# ISS_TOP register map
Vendor: Texas Instruments
Peripheral module from a debugger description file (folder omap4460).
Registers are 32-bit, access not given, reset 0x0 unless marked. A register's access mark holds for its fields unless they carry their own. Offsets are as the file gives them; lines under a group give offsets from that group; [hi:lo] are bit positions; {n}, {i} and the like mark numbered series; 'fields as' and 'values as' point back to an identical list; <NAME> marks a mode.

## ISS_TOP
0x00 ISS_HL_REVISION ro reset not defined — IP Revision Identifier (X.Y.R) Used by software to track features, bugs, and compatibility
  [31:0] REVISION — IP Revision
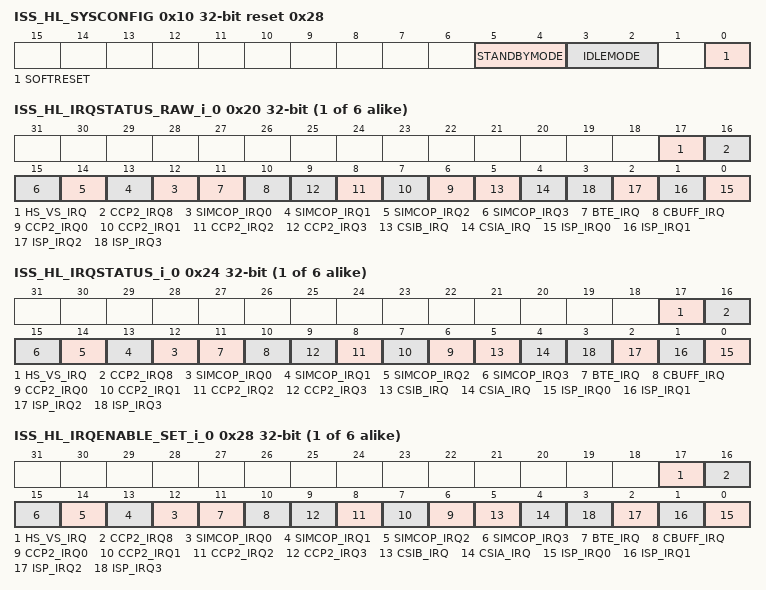
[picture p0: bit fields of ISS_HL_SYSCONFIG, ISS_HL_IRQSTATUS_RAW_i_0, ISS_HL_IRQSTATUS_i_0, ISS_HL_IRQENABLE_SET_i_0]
0x10 ISS_HL_SYSCONFIG access per field reset 0x28 — Clock management configuration
  [5:4] STANDBYMODE rw — Master interface power management, standby/Wait control
    0=Force-standby. MStandby is asserted unconditionally.; 1=No-standby. MStandby is never asserted.; 3=Smart-standby; 2=Smart-standby
  [3:2] IDLEMODE rw — IDLE protocol configuration
    0=Force-idle; 1=No-idle; 3=Smart-idle; 2=Smart-idle
  [0] SOFTRESET rw — Software reset.
    0=SOFTRESET_0_w (No action); 1=SOFTRESET_1_w (Initiate software reset); 1=SOFTRESET_1_r (Reset (software or other) ongoing); 0=SOFTRESET_0_r (Reset done, no pending action)
{0x20+0x10*i} ISS_HL_IRQSTATUS_RAW_i_{i} access per field (i=0..5) — Per-event raw interrupt status vector, line 0. Raw status is set even if event is not enabled by setting the register.
  [17] HS_VS_IRQ rw — HS or VS synchronization event. This event is triggered if a rising or falling edge is detected on the HS or VS signal (after the video port mux). The rising or falling edge and the HS or VS signal selection is chosen with the ISS_CTRL.SYNC_DETECT bit field.
    0=HS_VS_IRQ_0_w (No action); 1=HS_VS_IRQ_1_w (Set event (debug)); 1=HS_VS_IRQ_1_r (Event pending); 0=HS_VS_IRQ_0_r (No event pending)
  [16] CCP2_IRQ8 ro — Event generated by the CCP2 receiver
    1=CCP2_IRQ8_1_r (Event pending); 0=CCP2_IRQ8_0_r (No event pending)
  [n+12] SIMCOP_IRQ{n} ro (n=0..3) — Event generated by SIMCOP
    1=SIMCOP_IRQ{n}_1_r (Event pending); 0=SIMCOP_IRQ{n}_0_r (No event pending)
  [11] BTE_IRQ ro — Event generated by the burst translation engine
    1=BTE_IRQ_1_r (Event pending); 0=BTE_IRQ_0_r (No event pending)
  [10] CBUFF_IRQ ro — Event generated by the circular buffer
    1=CBUFF_IRQ_1_r (Event pending); 0=CBUFF_IRQ_0_r (No event pending)
  [n+6] CCP2_IRQ{n} ro (n=0..3) — Event generated by the CCP2 receiver
    1=CCP2_IRQ{n}_1_r (Event pending); 0=CCP2_IRQ{n}_0_r (No event pending)
  [5] CSIB_IRQ ro — Event generated by the CSI2 receiver #b
    1=CSIB_IRQ_1_r (Event pending); 0=CSIB_IRQ_0_r (No event pending)
  [4] CSIA_IRQ ro — Event generated by the CSI2 receiver #a
    1=CSIA_IRQ_1_r (Event pending); 0=CSIA_IRQ_0_r (No event pending)
  [n] ISP_IRQ{n} ro (n=0..3) — Combined interrupt event provided by the ISP.
    1=ISP_IRQ{n}_1_r (Event pending); 0=ISP_IRQ{n}_0_r (No event pending)
{0x24+0x10*i} ISS_HL_IRQSTATUS_i_{i} (i=0..5) — Per-event 'enabled' interrupt status vector, line 0. Enabled status is not set unless event is enabled by setting the register.
  [17] HS_VS_IRQ — HS or VS synchronization event. This event is triggered if a rising or falling edge is detected on the HS or VS signal (after the video port mux). The rising or falling edge and the HS or VS signal selection is chosen with the ISS_CTRL.SYNC_DETECT bit field. (access RW W1toSet)
    0=HS_VS_IRQ_0_w (No action); 1=HS_VS_IRQ_1_w (Clear (raw) event); 1=HS_VS_IRQ_1_r (Event pending); 0=HS_VS_IRQ_0_r (No (enabled) event pending)
  [16] CCP2_IRQ8 ro — Event generated by the CCP2 receiver
    1=CCP2_IRQ8_1_r (Event pending); 0=CCP2_IRQ8_0_r (No (enabled) event pending)
  [n+12] SIMCOP_IRQ{n} ro (n=0..3) — Event generated by SIMCOP
    1=SIMCOP_IRQ{n}_1_r (Event pending); 0=SIMCOP_IRQ{n}_0_r (No (enabled) event pending)
  [11] BTE_IRQ ro — Event generated by the burst translation engine
    1=BTE_IRQ_1_r (Event pending); 0=BTE_IRQ_0_r (No (enabled) event pending)
  [10] CBUFF_IRQ ro — Event generated by the circular buffer
    1=CBUFF_IRQ_1_r (Event pending); 0=CBUFF_IRQ_0_r (No (enabled) event pending)
  [n+6] CCP2_IRQ{n} ro (n=0..3) — Event generated by the CCP2 receiver
    1=CCP2_IRQ{n}_1_r (Event pending); 0=CCP2_IRQ{n}_0_r (No (enabled) event pending)
  [5] CSIB_IRQ ro — Event generated by the CSI2 receiver #b
    1=CSIB_IRQ_1_r (Event pending); 0=CSIB_IRQ_0_r (No (enabled) event pending)
  [4] CSIA_IRQ ro — Event generated by the CSI2 receiver #a
    1=CSIA_IRQ_1_r (Event pending); 0=CSIA_IRQ_0_r (No (enabled) event pending)
  [n] ISP_IRQ{n} ro (n=0..3) — Combined interrupt event provided by the ISP.
    1=ISP_IRQ{n}_1_r (Event pending); 0=ISP_IRQ{n}_0_r (No (enabled) event pending)
{0x28+0x10*i} ISS_HL_IRQENABLE_SET_i_{i} (i=0..5) — Per-event interrupt enable bit vector Write 1 to set (enable interrupt). Readout equal to corresponding _CLR register.
  [17] HS_VS_IRQ — HS or VS synchronization event. This event is triggered if a rising or falling edge is detected on the HS or VS signal (after the video port mux). The rising or falling edge and the HS or VS signal selection is chosen with the ISS_CTRL.SYNC_DETECT bit field. (access RW W1toSet)
    0=HS_VS_IRQ_0_w (No action); 1=HS_VS_IRQ_1_w (Enable interrupt); 1=HS_VS_IRQ_1_r (Interrupt enabled); 0=HS_VS_IRQ_0_r (Interrupt disabled (masked))
  [16] CCP2_IRQ8 — Event generated by the CCP2 receiver (access RW W1toSet)
    0=CCP2_IRQ8_0_w (No action Write 0x1: Enable interrupt); 1=CCP2_IRQ8_1_r (Interrupt enabled Read 0x0: Interrupt disabled (masked))
  [n+12] SIMCOP_IRQ{n} (n=0..3) — Event generated by SIMCOP (access RW W1toSet)
    0=SIMCOP_IRQ{n}_0_w (No action); 1=SIMCOP_IRQ{n}_1_w (Enable interrupt); 1=SIMCOP_IRQ{n}_1_r (Interrupt enabled); 0=SIMCOP_IRQ{n}_0_r (Interrupt disabled (masked))
  [11] BTE_IRQ — Event generated by the burst translation engine (access RW W1toSet)
    0=BTE_IRQ_0_w (No action); 1=BTE_IRQ_1_w (Enable interrupt); 1=BTE_IRQ_1_r (Interrupt enabled); 0=BTE_IRQ_0_r (Interrupt disabled (masked))
  [10] CBUFF_IRQ — Event generated by the circular buffer (access RW W1toSet)
    0=CBUFF_IRQ_0_w (No action); 1=CBUFF_IRQ_1_w (Enable interrupt); 1=CBUFF_IRQ_1_r (Interrupt enabled); 0=CBUFF_IRQ_0_r (Interrupt disabled (masked))
  [n+6] CCP2_IRQ{n} (n=0..3) — Event generated by the CCP2 receiver (access RW W1toSet)
    0=CCP2_IRQ{n}_0_w (No action); 1=CCP2_IRQ{n}_1_w (Enable interrupt); 1=CCP2_IRQ{n}_1_r (Interrupt enabled); 0=CCP2_IRQ{n}_0_r (Interrupt disabled (masked))
  [5] CSIB_IRQ — Event generated by the CSI2 receiver #b (access RW W1toSet)
    0=CSIB_IRQ_0_w (No action); 1=CSIB_IRQ_1_w (Enable interrupt); 1=CSIB_IRQ_1_r (Interrupt enabled); 0=CSIB_IRQ_0_r (Interrupt disabled (masked))
  [4] CSIA_IRQ — Event generated by the CSI2 receiver #a (access RW W1toSet)
    0=CSIA_IRQ_0_w (No action); 1=CSIA_IRQ_1_w (Enable interrupt); 1=CSIA_IRQ_1_r (Interrupt enabled); 0=CSIA_IRQ_0_r (Interrupt disabled (masked))
  [n] ISP_IRQ{n} (n=0..3) — Combined interrupt event provided by the ISP. (access RW W1toSet)
    0=ISP_IRQ{n}_0_w (No action); 1=ISP_IRQ{n}_1_w (Enable interrupt); 1=ISP_IRQ{n}_1_r (Interrupt enabled); 0=ISP_IRQ{n}_0_r (Interrupt disabled (masked))
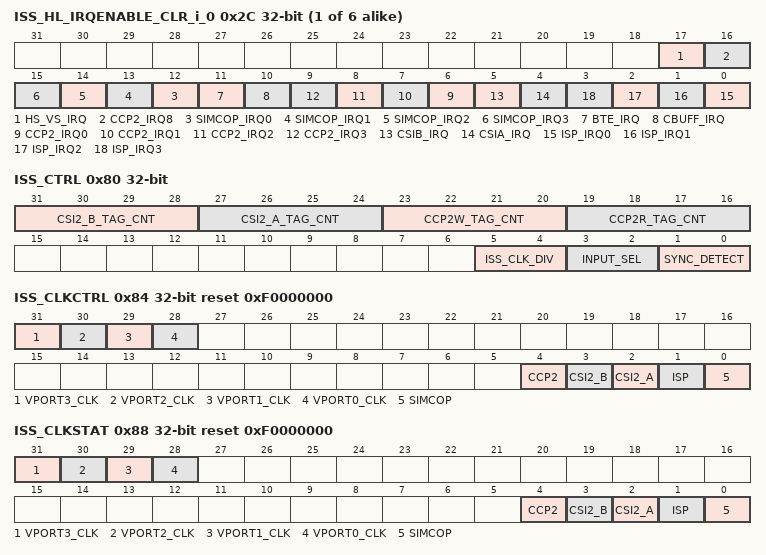
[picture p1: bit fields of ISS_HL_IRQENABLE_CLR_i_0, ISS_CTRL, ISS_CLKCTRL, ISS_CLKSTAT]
{0x2C+0x10*i} ISS_HL_IRQENABLE_CLR_i_{i} (i=0..5) — Per-event interrupt enable bit vector Write 1 to clear (disable interrupt). Readout equal to corresponding _SET register.
  [17] HS_VS_IRQ — HS or VS synchronization event. This event is triggered if a rising or falling edge is detected on the HS or VS signal (after the video port mux). The rising or falling edge and the HS or VS signal selection is chosen with the ISS_CTRL.SYNC_DETECT bit field. (access RW W1toClr)
    0=HS_VS_IRQ_0_w (No action); 1=HS_VS_IRQ_1_w (Disable interrupt); 1=HS_VS_IRQ_1_r (Interrupt enabled); 0=HS_VS_IRQ_0_r (Interrupt disabled (masked))
  [16] CCP2_IRQ8 — Event generated by the CCP2 receiver (access RW W1toSet)
    values as ISS_HL_IRQENABLE_SET_i_0.CCP2_IRQ8
  [n+12] SIMCOP_IRQ{n} (n=0..3) — Event generated by SIMCOP (access RW W1toClr)
    0=SIMCOP_IRQ{n}_0_w (No action); 1=SIMCOP_IRQ{n}_1_w (Disable interrupt); 1=SIMCOP_IRQ{n}_1_r (Interrupt enabled); 0=SIMCOP_IRQ{n}_0_r (Interrupt disabled (masked))
  [11] BTE_IRQ — Event generated by the BTE (access RW W1toClr)
    0=BTE_IRQ_0_w (No action); 1=BTE_IRQ_1_w (Disable interrupt); 1=BTE_IRQ_1_r (Interrupt enabled); 0=BTE_IRQ_0_r (Interrupt disabled (masked))
  [10] CBUFF_IRQ — Event generated by the CBUFF (access RW W1toClr)
    0=CBUFF_IRQ_0_w (No action); 1=CBUFF_IRQ_1_w (Disable interrupt); 1=CBUFF_IRQ_1_r (Interrupt enabled); 0=CBUFF_IRQ_0_r (Interrupt disabled (masked))
  [n+6] CCP2_IRQ{n} (n=0..3) — Event generated by the CCP2 receiver (access RW W1toClr)
    0=CCP2_IRQ{n}_0_w (No action); 1=CCP2_IRQ{n}_1_w (Disable interrupt); 1=CCP2_IRQ{n}_1_r (Interrupt enabled); 0=CCP2_IRQ{n}_0_r (Interrupt disabled (masked))
  [5] CSIB_IRQ — Event generated by the CSI2 receiver b (access RW W1toClr)
    0=CSIB_IRQ_0_w (No action); 1=CSIB_IRQ_1_w (Disable interrupt); 1=CSIB_IRQ_1_r (Interrupt enabled); 0=CSIB_IRQ_0_r (Interrupt disabled (masked))
  [4] CSIA_IRQ — Event generated by the CSI2 receiver a (access RW W1toClr)
    0=CSIA_IRQ_0_w (No action); 1=CSIA_IRQ_1_w (Disable interrupt); 1=CSIA_IRQ_1_r (Interrupt enabled); 0=CSIA_IRQ_0_r (Interrupt disabled (masked))
  [n] ISP_IRQ{n} (n=0..3) — Combined interrupt event provided by the ISP. (access RW W1toClr)
    0=ISP_IRQ{n}_0_w (No action); 1=ISP_IRQ{n}_1_w (Disable interrupt); 1=ISP_IRQ{n}_1_r (Interrupt enabled); 0=ISP_IRQ{n}_0_r (Interrupt disabled (masked))
0x80 ISS_CTRL access per field — ISS control register
  [31:28] CSI2_B_TAG_CNT rw — Defines the maximum number of tags that could be used by the CSI2 b write bridge. Note: Tag count must be set to 16 for best performance.
  [27:24] CSI2_A_TAG_CNT rw — Defines the maximum number of tags that could be used by the CSI2 a write bridge. Note: Tag count must be set to 16 for best performance.
  [23:20] CCP2W_TAG_CNT rw — Defines the maximum number of tags that could be used by the CCP2 write bridge Note: Tag count must be set to 16 for best performance.
  [19:16] CCP2R_TAG_CNT rw — Defines the maximum number of tags that could be used by the CCP2 read bridge Note: Tag count must be set to 16 for best performance.
  [5:4] ISS_CLK_DIV rw — ISS functional clock division CLK refers to the input clock provided to the ISS. FCLK is the functional clock provided to ISS top level and submodules. CFGCLK is the clock used for the configuration network.
    0=FCLK=CLK CFGCLK=CLK/2; 1=FCLK=CLK/2 CFGCLK=CLK/4; 2=FCLK=CLK/4 CFGCLK=CLK/8
  [3:2] INPUT_SEL rw — Selects ISP input
    0=CSI2-A; 1=CSI2-B; 2=CCP2; 3=Parallel interface
  [1:0] SYNC_DETECT rw — Chooses among rising and falling edge for the HS_VS_IRQ synchronization event
    0=HS falling edge; 1=HS raising edge; 3=VS raising edge; 2=VS falling edge
0x84 ISS_CLKCTRL access per field reset 0xF0000000 — ISS clock control register. Use to enable/disable the interface and functional clock of ISS submodules.
  [31] VPORT3_CLK rw — Enables the pixel clock from the parallel interface
    0=Disabled; 1=Enabled
  [30] VPORT2_CLK rw — Enables the pixel clock from the CCP2 protocol engine
    0=Disabled; 1=Enabled
  [29] VPORT1_CLK rw — Enables the pixel clock from the CSI2_B protocol engine
    0=Disabled; 1=Enabled
  [28] VPORT0_CLK rw — Enables the pixel clock from the CSI2_A protocol engine
    0=Disabled; 1=Enabled
  [4] CCP2 wo
    0=CCP2_0_w (Request shutdown of the submodule. No effect if the submodule clock is already off.); 1=CCP2_1_w (Request enable of the submodule. No effect if the submodule clock is already on.)
  [3] CSI2_B wo
    0=CSI2_B_0_w (Request shutdown of the submodule. No effect if the submodule clock is already off.); 1=CSI2_B_1_w (Request enable of the submodule. No effect if the submodule clock is already on.)
  [2] CSI2_A wo
    0=CSI2_A_0_w (Request shutdown of the submodule. No effect if the submodule clock is already off.); 1=CSI2_A_1_w (Request enable of the submodule. No effect if the submodule clock is already on.)
  [1] ISP wo
    0=ISP_0_w (Request shutdown of the submodule. No effect if the submodule clock is already off.); 1=ISP_1_w (Request enable of the submodule. No effect if the submodule clock is already on.)
  [0] SIMCOP wo
    0=SIMCOP_0_w (Request shutdown of the submodule. No effect if the submodule clock is already off.); 1=SIMCOP_1_w (Request enable of the submodule. No effect if the submodule clock is already on.)
0x88 ISS_CLKSTAT ro reset 0xF0000000 — ISS clock status register.
  [31] VPORT3_CLK — Status of the pixel clock from the parallel interface
    1=VPORT3_CLK_1_r (Enabled); 0=VPORT3_CLK_0_r (Disabled)
  [30] VPORT2_CLK — Status of the pixel clock from the CCP2 protocol engine
    1=VPORT2_CLK_1_r (Enabled); 0=VPORT2_CLK_0_r (Disabled)
  [29] VPORT1_CLK — Status of the pixel clock from the CSI2_B protocol engine
    1=VPORT1_CLK_1_r (Enabled); 0=VPORT1_CLK_0_r (Disabled)
  [28] VPORT0_CLK — Status of the pixel clock from the CSI2_A protocol engine
    1=VPORT0_CLK_1_r (Enabled); 0=VPORT0_CLK_0_r (Disabled)
  [4] CCP2
    1=CCP2_1_r (The submodule is on.); 0=CCP2_0_r (The submodule is off.)
  [3] CSI2_B
    1=CSI2_B_1_r (The submodule is on.); 0=CSI2_B_0_r (The submodule is off.)
  [2] CSI2_A
    1=CSI2_A_1_r (The submodule is on.); 0=CSI2_A_0_r (The submodule is off.)
  [1] ISP
    1=ISP_1_r (The submodule is on.); 0=ISP_0_r (The submodule is off.)
  [0] SIMCOP
    1=SIMCOP_1_r (The submodule is on.); 0=SIMCOP_0_r (The submodule is off.)
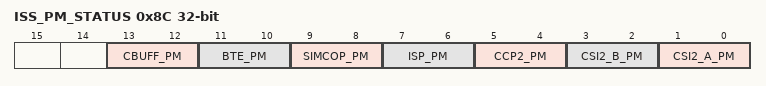
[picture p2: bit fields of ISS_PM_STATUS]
0x8C ISS_PM_STATUS ro — ISS power manager status register. Software could know what modules are in functional or STANDBY/IDLE state. This feature could be particularly useful to debug when ISS does not go into STANDBY mode
  [13:12] CBUFF_PM — Power status of the CBUFF.
    2=CBUFF_PM_2_r (Functional); 1=CBUFF_PM_1_r (Transition); 0=CBUFF_PM_0_r (Idle)
  [11:10] BTE_PM — Power status of the BTE.
    2=BTE_PM_2_r (Functional); 1=BTE_PM_1_r (Transition); 0=BTE_PM_0_r (Idle)
  [9:8] SIMCOP_PM — Power status of the SIMCOP.
    2=SIMCOP_PM_2_r (Functional); 1=SIMCOP_PM_1_r (Transition); 0=SIMCOP_PM_0_r (Standby)
  [7:6] ISP_PM — Power status of the ISP.
    2=ISP_PM_2_r (Functional); 1=ISP_PM_1_r (Transition); 0=ISP_PM_0_r (Standby)
  [5:4] CCP2_PM — Power status of the CCP2.
    2=CCP2_PM_2_r (Functional); 1=CCP2_PM_1_r (Transition); 0=CCP2_PM_0_r (Standby)
  [3:2] CSI2_B_PM — Power status of the CSI2 module b
    2=CSI2_B_PM_2_r (Functional); 1=CSI2_B_PM_1_r (Transition); 0=CSI2_B_PM_0_r (Standby)
  [1:0] CSI2_A_PM — Power status of the CSI2 module a
    2=CSI2_A_PM_2_r (Functional); 1=CSI2_A_PM_1_r (Transition); 0=CSI2_A_PM_0_r (Standby)
